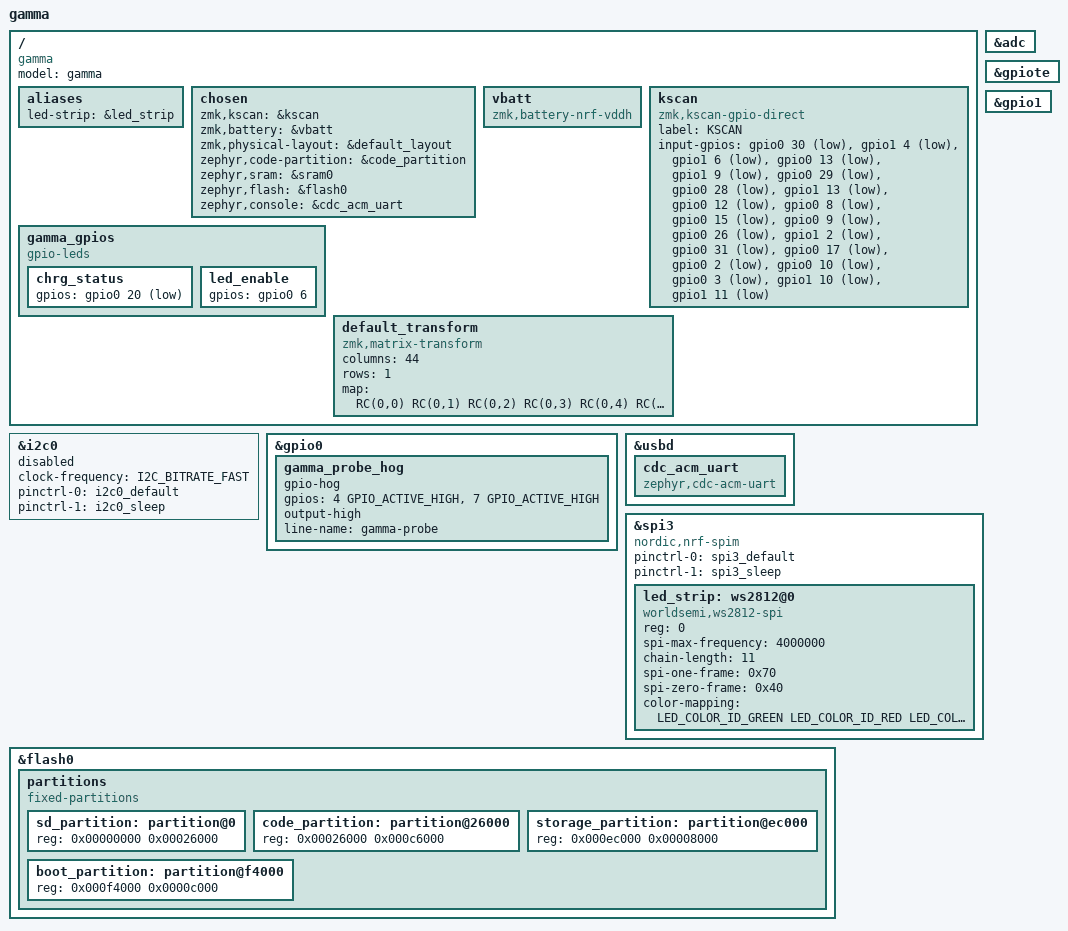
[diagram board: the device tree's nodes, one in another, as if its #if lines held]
// See https://docs.zephyrproject.org/4.1.0/hardware/porting/board_porting.html
// and https://zmk.dev/docs/development/hardware-integration/new-shield for more
// instructions.

/dts-v1/;
#include <nordic/nrf52840_qiaa.dtsi>
#include <dt-bindings/zmk/matrix_transform.h>
#include <dt-bindings/led/led.h>

#include "gamma-layouts.dtsi"

/ {
    model = "gamma";
    compatible = "gamma";

    aliases {
        led-strip = &led_strip;
    };

    chosen {
        zmk,kscan = &kscan;
        zmk,battery = &vbatt;
        zmk,physical-layout = &default_layout;
        zephyr,code-partition = &code_partition;
        zephyr,sram = &sram0;
        zephyr,flash = &flash0;
        zephyr,console = &cdc_acm_uart;
    };

    vbatt: vbatt {
        compatible = "zmk,battery-nrf-vddh";
    };

    kscan: kscan {
        compatible = "zmk,kscan-gpio-direct";
        label = "KSCAN";

        input-gpios
            = <&gpio0 30 (GPIO_ACTIVE_LOW | GPIO_PULL_UP)>
            , <&gpio1 4 (GPIO_ACTIVE_LOW | GPIO_PULL_UP)>
            , <&gpio1 6 (GPIO_ACTIVE_LOW | GPIO_PULL_UP)>
            , <&gpio0 13 (GPIO_ACTIVE_LOW | GPIO_PULL_UP)>
            , <&gpio1 9 (GPIO_ACTIVE_LOW | GPIO_PULL_UP)>
            , <&gpio0 29 (GPIO_ACTIVE_LOW | GPIO_PULL_UP)>
            , <&gpio0 28 (GPIO_ACTIVE_LOW | GPIO_PULL_UP)>
            , <&gpio1 13 (GPIO_ACTIVE_LOW | GPIO_PULL_UP)>
            , <&gpio0 12 (GPIO_ACTIVE_LOW | GPIO_PULL_UP)>
            , <&gpio0 8 (GPIO_ACTIVE_LOW | GPIO_PULL_UP)>
            , <&gpio0 15 (GPIO_ACTIVE_LOW | GPIO_PULL_UP)>
            , <&gpio0 9 (GPIO_ACTIVE_LOW | GPIO_PULL_UP)>
            , <&gpio0 26 (GPIO_ACTIVE_LOW | GPIO_PULL_UP)>
            , <&gpio1 2 (GPIO_ACTIVE_LOW | GPIO_PULL_UP)>
            , <&gpio0 31 (GPIO_ACTIVE_LOW | GPIO_PULL_UP)>
            , <&gpio0 17 (GPIO_ACTIVE_LOW | GPIO_PULL_UP)>
            , <&gpio0 2 (GPIO_ACTIVE_LOW | GPIO_PULL_UP)>
            , <&gpio0 10 (GPIO_ACTIVE_LOW | GPIO_PULL_UP)>
            , <&gpio0 3 (GPIO_ACTIVE_LOW | GPIO_PULL_UP)>
            , <&gpio1 10 (GPIO_ACTIVE_LOW | GPIO_PULL_UP)>
            , <&gpio1 11 (GPIO_ACTIVE_LOW | GPIO_PULL_UP)>
            ;
    };

    gamma_gpios {
        compatible = "gpio-leds";

        chrg_status: chrg_status {
            gpios = <&gpio0 20 (GPIO_ACTIVE_LOW | GPIO_PULL_UP)>;
        };
        led_enable: led_enable {
            gpios = <&gpio0 6 (GPIO_ACTIVE_HIGH | GPIO_PULL_DOWN)>;
        };
    };

    default_transform: default_transform {
        compatible = "zmk,matrix-transform";
        columns = <44>;
        rows = <1>;
        map = <
            RC(0,0)  RC(0,1)  RC(0,2)  RC(0,3)  RC(0,4)  RC(0,5)  RC(0,27) RC(0,26) RC(0,25) RC(0,24) RC(0,23) RC(0,22)
            RC(0,6)  RC(0,7)  RC(0,8)  RC(0,9)  RC(0,10) RC(0,11) RC(0,33) RC(0,32) RC(0,31) RC(0,30) RC(0,29) RC(0,28)
            RC(0,12) RC(0,13) RC(0,14) RC(0,15) RC(0,16) RC(0,17) RC(0,39) RC(0,38) RC(0,37) RC(0,36) RC(0,35) RC(0,34)
                               RC(0,18) RC(0,19) RC(0,20) RC(0,42) RC(0,41) RC(0,40)
        >;
    };
};

&i2c0 {
    status = "okay";
    clock-frequency = <I2C_BITRATE_FAST>;
    pinctrl-0 = <&i2c0_default>;
    pinctrl-1 = <&i2c0_sleep>;
    pinctrl-names = "default", "sleep";
};

#if defined(CONFIG_GAMMA_LED_PROBE)
&i2c0 {
    status = "disabled";
};
#endif

&adc {
    status = "okay";
};

&gpiote {
    status = "okay";
};

&gpio0 {
    status = "okay";
};

&gpio1 {
    status = "okay";
};

#if defined(CONFIG_GAMMA_LED_PROBE)
&gpio0 {
    gamma_probe_hog: gamma_probe_hog {
        gpio-hog;
        gpios = <4 GPIO_ACTIVE_HIGH>, <7 GPIO_ACTIVE_HIGH>;
        output-high;
        line-name = "gamma-probe";
    };
};
#endif

zephyr_udc0: &usbd {
    status = "okay";
    cdc_acm_uart: cdc_acm_uart {
        compatible = "zephyr,cdc-acm-uart";
    };
};

&spi3 {
    compatible = "nordic,nrf-spim";
    status = "okay";

    pinctrl-0 = <&spi3_default>;
    pinctrl-1 = <&spi3_sleep>;
    pinctrl-names = "default", "sleep";

    led_strip: ws2812@0 {
        compatible = "worldsemi,ws2812-spi";

        reg = <0>;
        spi-max-frequency = <4000000>;
        chain-length = <11>;
        spi-one-frame = <0x70>;
        spi-zero-frame = <0x40>;
        color-mapping = <LED_COLOR_ID_GREEN LED_COLOR_ID_RED LED_COLOR_ID_BLUE>;
    };
};

&flash0 {
    partitions {
        compatible = "fixed-partitions";
        #address-cells = <1>;
        #size-cells = <1>;

        sd_partition: partition@0 {
            reg = <0x00000000 0x00026000>;
        };
        code_partition: partition@26000 {
            reg = <0x00026000 0x000c6000>;
        };

        storage_partition: partition@ec000 {
            reg = <0x000ec000 0x00008000>;
        };

        boot_partition: partition@f4000 {
            reg = <0x000f4000 0x0000c000>;
        };
    };
};
